# earlgrey register map
Vendor: lowRISC; File version: 0.1
CPU: ibex rev01, little endian, no MPU, no FPU, VTOR, 2 interrupt priority bits, 2 interrupts
Registers are 32-bit, read-write, no defined reset value unless marked. A register's access mark holds for its fields unless they carry their own. Offsets are from the block's base; [hi:lo] are bit positions.

## ENTROPY_SRC — Filters and checks raw entropy bits from a random noise source and forwards them to CSRNG
Base 0x41160000
0x40 ME_REGWEN — Register write enable for module enable register
  [0] Value — When true, the !!MODULE_ENABLE register can be modified.When false, it becomes read-only.
0x44 SW_REGUPD — Register write enable for control and threshold registers
  [0] Value — When this bit true and the MODULE_ENABLE field is false,the REGWEN write enable bit read as true, and is distributed toall associated control and threshold registers.When false, these registers become read-only.
0x48 REGWEN ro — Register write enable for all control registers
  [0] Value — This read-only write enable bit will allow write access to control and threshold registers that are associated with this bit, but only when the !!MODULE_ENABLE register is set to `kMultiBitBool4False` and the !!SW_REGUPD write enable bit is set to true.When read as false, these registers become read-only.
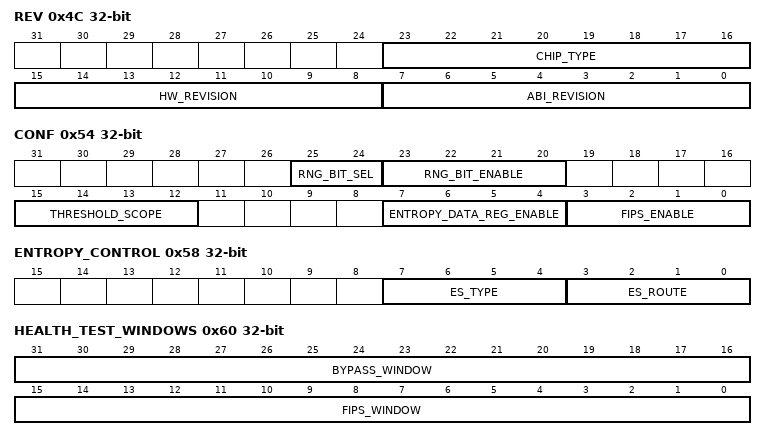
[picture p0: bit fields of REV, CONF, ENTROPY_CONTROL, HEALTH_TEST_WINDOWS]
0x4C REV ro — Revision register
  [23:16] CHIP_TYPE — Read of this register shows the type of chip using this block.
  [15:8] HW_REVISION — Read of this register shows the revision of this block.
  [7:0] ABI_REVISION — Read of this register shows the ABI of this block.
0x50 MODULE_ENABLE
  [3:0] MODULE_ENABLE — Setting this field to `kMultiBitBool4True` will enable the ENTROPY_SRC module. Setting this field to `kMultiBitBool4False` will effectively reset the module.The modules of the entropy complex may only be enabled and disabled in a specific order, see Programmers Guide for details.
0x54 CONF — Configuration register
  [25:24] RNG_BIT_SEL — When the above bit iset, this field selects which bit from the RNG bus willbe processed when in single RNG bit mode.This two bit field selects the RNG bit stream:0b00: RNG bit 00b01: RNG bit 10b10: RNG bit 20b11: RNG bit 3
  [23:20] RNG_BIT_ENABLE — Setting this field to `kMultiBitBool4True` enables the single RNG bit mode, where only one bit is sampled.Note that the ENTROPY_SRC block can only generate FIPS qualified entropy if this field is set to `kMultiBitBool4False`.Additional requirements to generate FIPS qualified entropy are i) that !!CONF.FIPS_ENABLE is set to `kMultiBitBool4True`, and ii) that at most one of the !!ENTROPY_CONTROL.ES_ROUTE and !!ENTROPY_CONTROL.ES_TYPE fields but not both are set to `kMultiBitBool4True`.
  [15:12] THRESHOLD_SCOPE — This field controls the scope (either by-line or by-sum) of the health checks.If set to `kMultiBitBool4True`, the Adaptive Proportion and Markov Tests will accumulate all RNG input lines into a single score, and thresholds will be applied to the sum all the entropy input lines.If set to `kMultiBitBool4False`, the RNG input lines are all scored individually.A statistical deviation in any one input line, be it due to coincidence or failure, will force rejection of the sample, and count toward the total alert count.
  [7:4] ENTROPY_DATA_REG_ENABLE — Setting this field to `kMultiBitBool4True` will enable reading entropy values from the !!ENTROPY_DATA register.This function also requires that the otp_en_entropy_src_fw_read input is set to `kMultiBitBool8True`.
  [3:0] FIPS_ENABLE — Setting this field to `kMultiBitBool4True` selects the FIPS/CC compliant mode (or short FIPS mode).In this mode, the ENTROPY_SRC block can generate FIPS qualified entropy.Additional requirements to generate FIPS qualified entropy are i) that at most one of the !!ENTROPY_CONTROL.ES_ROUTE and !!ENTROPY_CONTROL.ES_TYPE fields are set to `kMultiBitBool4True` but not both, and ii) that !!CONF.RNG_BIT_ENABLE is set to `kMultiBitBool4False`.Setting this field to `kMultiBitBool4False` selects the boot-time / bypass mode in which the hardware conditioning is bypassed.
0x58 ENTROPY_CONTROL
  [7:4] ES_TYPE — When this field is `kMultiBitBool4False`, the hardware conditioning inside the ENTROPY_SRC block is enabled.Setting this field to `kMultiBitBool4True` will bypass the hardware conditioning.For this to work, also !!ENTROPY_CONTROL.ES_ROUTE needs to be set to `kMultiBitBool4True` to route the unconditioned, raw entropy to the !!ENTROPY_DATA register.Alternatively, the hardware conditioning can be bypassed by setting !!CONF.FIPS_ENABLE to `kMultiBitBool4False` to disable FIPS mode and enable bypass / boot-time mode.In both cases, the ENTROPY_SRC block will not generate FIPS qualified entropy.To generate FIPS qualified entropy, i) !!CONF.FIPS_ENABLE needs to be set to `kMultiBitBool4True`, ii) !!CONF.RNG_BIT_ENABLE needs to be set to `kMultiBitBool4False`, and iii) at most one of the !!ENTROPY_CONTROL.ES_ROUTE and !!ENTROPY_CONTROL.ES_TYPE fields needs to be set to `kMultiBitBool4True` but not both.
  [3:0] ES_ROUTE — When this field is `kMultiBitBool4False`, the generated entropy will be forwarded out of this module to the hardware interface.Setting this field to `kMultiBitBool4True` routes the generated entropy to the !!ENTROPY_DATA register to be read by firmware.Note that for !!ENTROPY_DATA to become readable, also !!CONF.ENTROPY_DATA_REG_ENABLE needs to be set to `kMultiBitBool4True`.In addition, the otp_en_entropy_src_fw_read input needs to be set to `kMultiBitBool8True`.
0x5C ENTROPY_DATA ro — Entropy data bits
  [31:0] Value — A read of this register provides generated entropy bits to firmware.For this to work also !!CONF.ENTROPY_DATA_REG_ENABLE needs to be set to `kMultiBitBool4True`.In addition, the otp_en_entropy_src_fw_read input needs to be set to `kMultiBitBool8True`.
0x60 HEALTH_TEST_WINDOWS
  [31:16] BYPASS_WINDOW — This is the window size for all health tests when running in bypass mode.This mode is active after reset for the first and only test run, or when this mode is programmed by firmware by setting !!CONF.FIPS_ENABLE to `kMultiBitBool4False`.The default value is (384 bits * 1 clock/4 bits);Note that currently only a window size of 384 is supported and tested (this corresponds to the register default value 0x60).Do not use any other values, unless you know what you are doing.
  [15:0] FIPS_WINDOW — This is the window size for all health tests.This value is used when entropy is being tested in FIPS/CC compliance mode (for simplicity referred to as FIPS mode).The default value is (2048 bits * 1 clock/4 bits);
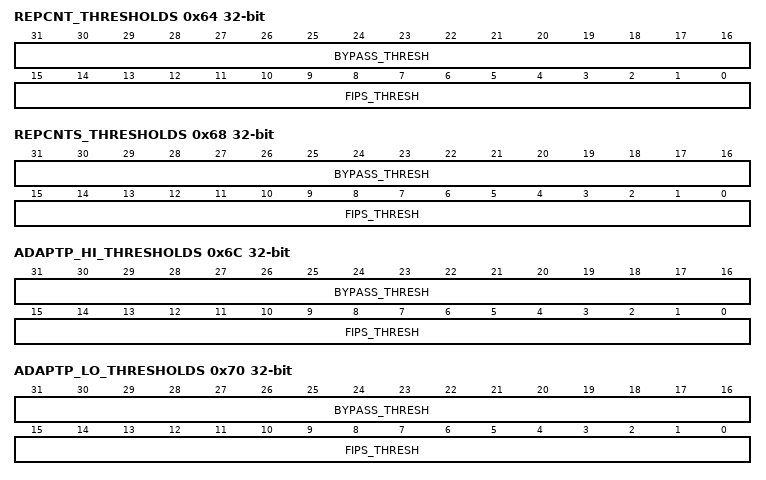
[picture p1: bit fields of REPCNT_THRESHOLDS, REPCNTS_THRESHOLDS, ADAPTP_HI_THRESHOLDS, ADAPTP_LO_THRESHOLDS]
0x64 REPCNT_THRESHOLDS — Repetition count test thresholds register
  [31:16] BYPASS_THRESH — This is the threshold size for the repetition count health test running in bypass mode. This mode is active after reset for the first and only test run, or when this mode is programmed by firmware. This register must be written before the module is enabled. Writing to this register will only update the register if the written value is less than the current value of this register. A read from this register always reflects the current value.
  [15:0] FIPS_THRESH — This is the threshold size for the repetition count health test. This value is used in FIPS mode. This register must be written before the module is enabled. Writing to this register will only update the register if the written value is less than the current value of this register. A read from this register always reflects the current value.
0x68 REPCNTS_THRESHOLDS — Repetition count symbol test thresholds register
  [31:16] BYPASS_THRESH — This is the threshold size for the repetition count symbol health test running in bypass mode. This mode is active after reset for the first and only test run, or when this mode is programmed by firmware. This register must be written before the module is enabled. Writing to this register will only update the register if the written value is less than the current value of this register. A read from this register always reflects the current value.
  [15:0] FIPS_THRESH — This is the threshold size for the repetition count symbol health test. This value is used in FIPS mode. This register must be written before the module is enabled. Writing to this register will only update the register if the written value is less than the current value of this register. A read from this register always reflects the current value.
0x6C ADAPTP_HI_THRESHOLDS — Adaptive proportion test high thresholds register
  [31:16] BYPASS_THRESH — This is the threshold size for the adaptive proportion health test running in bypass mode. This mode is active after reset for the first and only test run, or when this mode is programmed by firmware. This register must be written before the module is enabled. Writing to this register will only update the register if the written value is less than the current value of this register. A read from this register always reflects the current value.
  [15:0] FIPS_THRESH — This is the threshold size for the adaptive proportion health test. This value is used in FIPS mode. This register must be written before the module is enabled. Writing to this register will only update the register if the written value is less than the current value of this register. A read from this register always reflects the current value.
0x70 ADAPTP_LO_THRESHOLDS — Adaptive proportion test low thresholds register
  [31:16] BYPASS_THRESH — This is the threshold size for the adaptive proportion health test running in bypass mode. This mode is active after reset for the first and only test run, or when this mode is programmed by firmware. This register must be written before the module is enabled. Writing to this register will only update the register if the written value is greater than the current value of this register. A read from this register always reflects the current value.
  [15:0] FIPS_THRESH — This is the threshold size for the adaptive proportion health test. This value is used in FIPS mode. This register must be written before the module is enabled. Writing to this register will only update the register if the written value is greater than the current value of this register. A read from this register always reflects the current value.
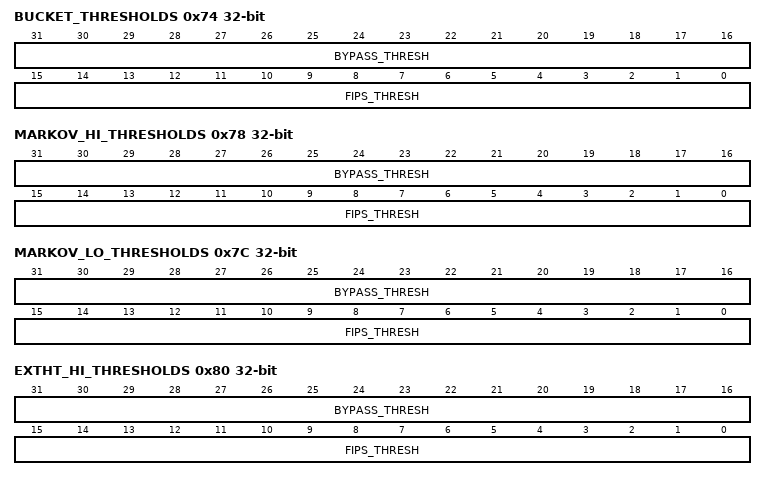
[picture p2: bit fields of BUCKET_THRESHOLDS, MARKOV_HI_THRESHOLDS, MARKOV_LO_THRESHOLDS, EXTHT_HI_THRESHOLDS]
0x74 BUCKET_THRESHOLDS — Bucket test thresholds register
  [31:16] BYPASS_THRESH — This is the threshold size for the bucket health test running in bypass mode. This mode is active after reset for the first and only test run, or when this mode is programmed by firmware. This register must be written before the module is enabled. Writing to this register will only update the register if the written value is less than the current value of this register. A read from this register always reflects the current value.
  [15:0] FIPS_THRESH — This is the threshold size for the bucket health test. This value is used in FIPS mode. This register must be written before the module is enabled. Writing to this register will only update the register if the written value is less than the current value of this register. A read from this register always reflects the current value.
0x78 MARKOV_HI_THRESHOLDS — Markov test high thresholds register
  [31:16] BYPASS_THRESH — This is the threshold size for the Markov health test running in bypass mode. This mode is active after reset for the first and only test run, or when this mode is programmed by firmware. This register must be written before the module is enabled. Writing to this register will only update the register if the written value is less than the current value of this register. A read from this register always reflects the current value.
  [15:0] FIPS_THRESH — This is the threshold size for the Markov health test. This value is used in FIPS mode. This register must be written before the module is enabled. Writing to this register will only update the register if the written value is less than the current value of this register. A read from this register always reflects the current value.
0x7C MARKOV_LO_THRESHOLDS — Markov test low thresholds register
  [31:16] BYPASS_THRESH — This is the threshold size for the Markov health test running in bypass mode. This mode is active after reset for the first and only test run, or when this mode is programmed by firmware. This register must be written before the module is enabled. Writing to this register will only update the register if the written value is greater than the current value of this register. A read from this register always reflects the current value.
  [15:0] FIPS_THRESH — This is the threshold size for the Markov health test. This value is used in FIPS mode. This register must be written before the module is enabled. Writing to this register will only update the register if the written value is greater than the current value of this register. A read from this register always reflects the current value.
0x80 EXTHT_HI_THRESHOLDS — External health test high thresholds register
  [31:16] BYPASS_THRESH — This is the threshold size for the external health test running in bypass mode. This mode is active after reset for the first and only test run, or when this mode is programmed by firmware. This register must be written before the module is enabled. Writing to this register will only update the register if the written value is less than the current value of this register. A read from this register always reflects the current value.
  [15:0] FIPS_THRESH — This is the threshold size for the external health test. This value is used in FIPS mode. This register must be written before the module is enabled. Writing to this register will only update the register if the written value is less than the current value of this register. A read from this register always reflects the current value.
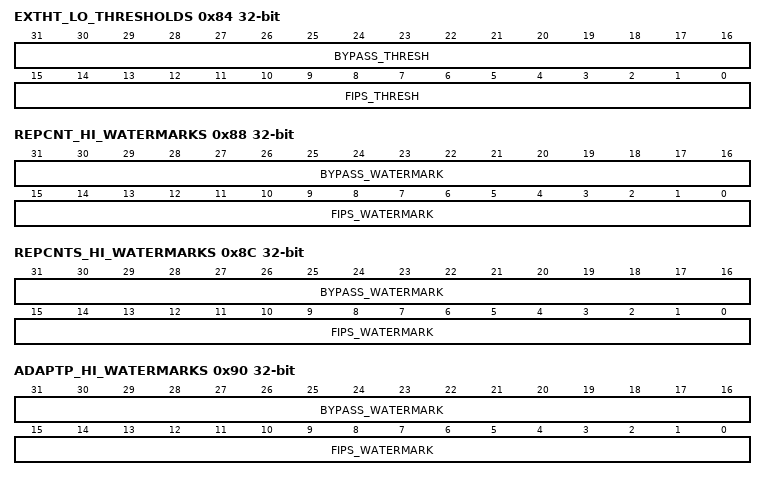
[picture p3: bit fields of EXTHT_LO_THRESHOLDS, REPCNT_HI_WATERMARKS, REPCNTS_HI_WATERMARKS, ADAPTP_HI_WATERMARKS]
0x84 EXTHT_LO_THRESHOLDS — External health test low thresholds register
  [31:16] BYPASS_THRESH — This is the threshold size for the external health test running in bypass mode. This mode is active after reset for the first and only test run, or when this mode is programmed by firmware. This register must be written before the module is enabled. Writing to this register will only update the register if the written value is greater than the current value of this register. A read from this register always reflects the current value.
  [15:0] FIPS_THRESH — This is the threshold size for the external health test. This value is used in FIPS mode. This register must be written before the module is enabled. Writing to this register will only update the register if the written value is greater than the current value of this register. A read from this register always reflects the current value.
0x88 REPCNT_HI_WATERMARKS ro — Repetition count test high watermarks register
  [31:16] BYPASS_WATERMARK — High watermark value of the REPCNT test in bypass mode.
  [15:0] FIPS_WATERMARK — High watermark value of the REPCNT test in FIPS mode.
0x8C REPCNTS_HI_WATERMARKS ro — Repetition count symbol test high watermarks register
  [31:16] BYPASS_WATERMARK — High watermark value of the REPCNTS test in bypass mode.
  [15:0] FIPS_WATERMARK — High watermark value of the REPCNTS test in FIPS mode.
0x90 ADAPTP_HI_WATERMARKS ro — Adaptive proportion test high watermarks register
  [31:16] BYPASS_WATERMARK — High watermark value of the adaptive proportion test in bypass mode.
  [15:0] FIPS_WATERMARK — High watermark value of the adaptive proportion test in FIPS mode.
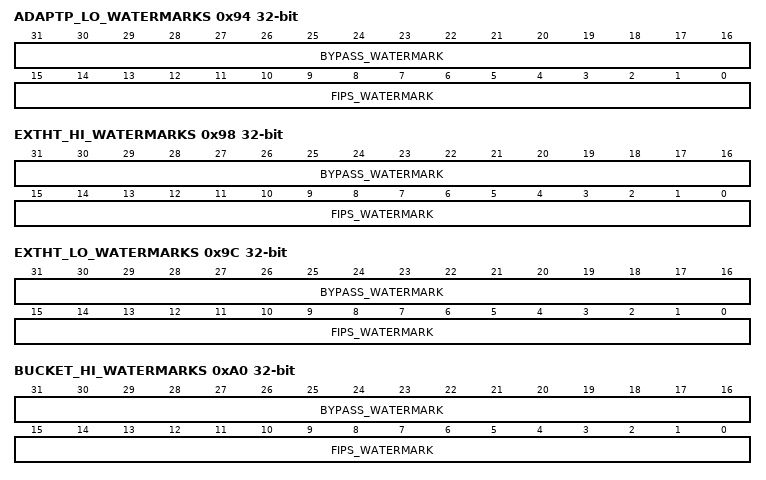
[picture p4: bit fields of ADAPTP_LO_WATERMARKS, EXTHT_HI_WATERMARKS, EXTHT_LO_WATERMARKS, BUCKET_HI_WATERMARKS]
0x94 ADAPTP_LO_WATERMARKS ro — Adaptive proportion test low watermarks register
  [31:16] BYPASS_WATERMARK — Low watermark value of the adaptive proportion test in bypass mode.
  [15:0] FIPS_WATERMARK — Low watermark value of the adaptive proportion test in FIPS mode.
0x98 EXTHT_HI_WATERMARKS ro — External health test high watermarks register
  [31:16] BYPASS_WATERMARK — High watermark value of the external health test in bypass mode.
  [15:0] FIPS_WATERMARK — High watermark value of the external health test in FIPS mode.
0x9C EXTHT_LO_WATERMARKS ro — External health test low watermarks register
  [31:16] BYPASS_WATERMARK — Low watermark value of the external health test in bypass mode.
  [15:0] FIPS_WATERMARK — Low watermark value of the external health test in FIPS mode.
0xA0 BUCKET_HI_WATERMARKS ro — Bucket test high watermarks register
  [31:16] BYPASS_WATERMARK — High watermark value of the bucket test in bypass mode.
  [15:0] FIPS_WATERMARK — High watermark value of the bucket test in FIPS mode.
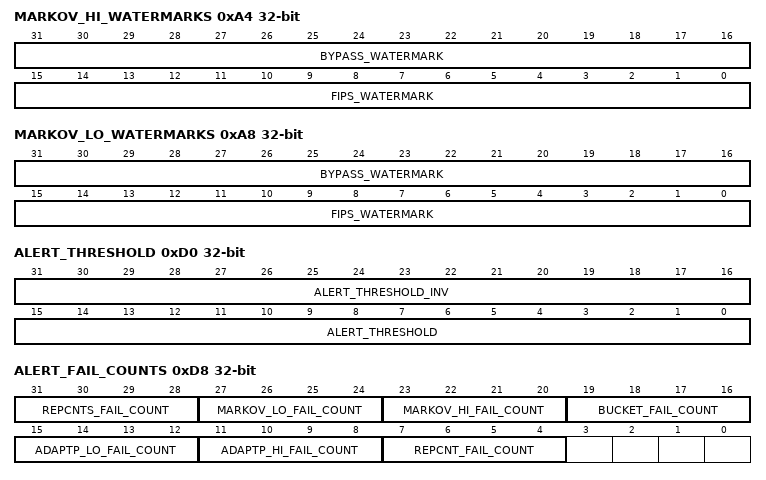
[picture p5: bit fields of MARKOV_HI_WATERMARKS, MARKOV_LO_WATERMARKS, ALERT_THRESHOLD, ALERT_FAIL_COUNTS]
0xA4 MARKOV_HI_WATERMARKS ro — Markov test high watermarks register
  [31:16] BYPASS_WATERMARK — High watermark value of the Markov test in bypass mode.
  [15:0] FIPS_WATERMARK — High watermark value of the Markov test in FIPS mode.
0xA8 MARKOV_LO_WATERMARKS ro — Markov test low watermarks register
  [31:16] BYPASS_WATERMARK — Low watermark value of the Markov test in bypass mode.
  [15:0] FIPS_WATERMARK — Low watermark value of the Markov test in FIPS mode.
0xAC REPCNT_TOTAL_FAILS ro — Repetition count test failure counter register
  [31:0] REPCNT_TOTAL_FAILS — This register will hold a running count of test failures observed during normal operation. It will persist until cleared.
0xB0 REPCNTS_TOTAL_FAILS ro — Repetition count symbol test failure counter register
  [31:0] REPCNTS_TOTAL_FAILS — This register will hold a running count of test failures observed during normal operation. It will persist until cleared.
0xB4 ADAPTP_HI_TOTAL_FAILS ro — Adaptive proportion high test failure counter register
  [31:0] ADAPTP_HI_TOTAL_FAILS — This register will hold a running count of test failures observed during normal operation. It will persist until cleared.
0xB8 ADAPTP_LO_TOTAL_FAILS ro — Adaptive proportion low test failure counter register
  [31:0] ADAPTP_LO_TOTAL_FAILS — This register will hold a running count of test failures observed during normal operation. It will persist until cleared.
0xBC BUCKET_TOTAL_FAILS ro — Bucket test failure counter register
  [31:0] BUCKET_TOTAL_FAILS — This register will hold a running count of test failures observed during normal operation. It will persist until cleared.
0xC0 MARKOV_HI_TOTAL_FAILS ro — Markov high test failure counter register
  [31:0] MARKOV_HI_TOTAL_FAILS — This register will hold a running count of test failures observed during normal operation. It will persist until cleared.
0xC4 MARKOV_LO_TOTAL_FAILS ro — Markov low test failure counter register
  [31:0] MARKOV_LO_TOTAL_FAILS — This register will hold a running count of test failures observed during normal operation. It will persist until cleared.
0xC8 EXTHT_HI_TOTAL_FAILS ro — External health test high threshold failure counter register
  [31:0] EXTHT_HI_TOTAL_FAILS — This register will hold a running count of test failures observed during normal operation. It will persist until cleared.
0xCC EXTHT_LO_TOTAL_FAILS ro — External health test low threshold failure counter register
  [31:0] EXTHT_LO_TOTAL_FAILS — This register will hold a running count of test failures observed during normal operation. It will persist until cleared.
0xD0 ALERT_THRESHOLD
  [31:16] ALERT_THRESHOLD_INV — This should be set to the value above, but inverted.
  [15:0] ALERT_THRESHOLD — This is the threshold size that will signal an alert when value is reached. A value of zero will disable alerts. The default value is 2.
0xD4 ALERT_SUMMARY_FAIL_COUNTS ro — Alert summary failure counts register
  [15:0] ANY_FAIL_COUNT — This field will hold a running count of the total alert count, which is a sum of all of the other counters in the !!ALERT_FAIL_COUNTS register. It will be reset after every passing test sequence unless in firmware override mode (extract and insert only). If an alert is signaled, this value will persist until it is cleared.
0xD8 ALERT_FAIL_COUNTS ro — Alert failure counts register
  [31:28] REPCNTS_FAIL_COUNT — This field will hold a running count of test failures that contribute to the total alert count. It will be reset after every passing test sequence unless in firmware override mode (extract and insert only). If an alert is signaled, this value will persist until it is cleared.
  [27:24] MARKOV_LO_FAIL_COUNT — This field will hold a running count of test failures that contribute to the total alert count. It will be reset after every passing test sequence unless in firmware override mode (extract and insert only). If an alert is signaled, this value will persist until it is cleared.
  [23:20] MARKOV_HI_FAIL_COUNT — This field will hold a running count of test failures that contribute to the total alert count. It will be reset after every passing test sequence unless in firmware override mode (extract and insert only). If an alert is signaled, this value will persist until it is cleared.
  [19:16] BUCKET_FAIL_COUNT — This field will hold a running count of test failures that contribute to the total alert count. It will be reset after every passing test sequence unless in firmware override mode (extract and insert only). If an alert is signaled, this value will persist until it is cleared.
  [15:12] ADAPTP_LO_FAIL_COUNT — This field will hold a running count of test failures that contribute to the total alert count. It will be reset after every passing test sequence unless in firmware override mode (extract and insert only). If an alert is signaled, this value will persist until it is cleared.
  [11:8] ADAPTP_HI_FAIL_COUNT — This field will hold a running count of test failures that contribute to the total alert count. It will be reset after every passing test sequence unless in firmware override mode (extract and insert only). If an alert is signaled, this value will persist until it is cleared.
  [7:4] REPCNT_FAIL_COUNT — This field will hold a running count of test failures that contribute to the total alert count. It will be reset after every passing test sequence unless in firmware override mode (extract and insert only). If an alert is signaled, this value will persist until it is cleared.
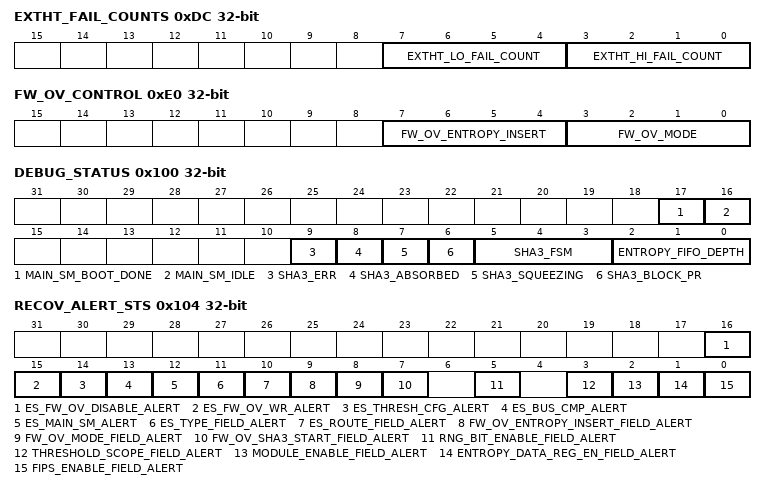
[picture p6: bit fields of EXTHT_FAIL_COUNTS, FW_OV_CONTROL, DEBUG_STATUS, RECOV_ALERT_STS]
0xDC EXTHT_FAIL_COUNTS ro — External health test alert failure counts register
  [7:4] EXTHT_LO_FAIL_COUNT — This field will hold a running count of test failures that contribute to the total alert count. It will be reset after every passing test sequence unless in firmware override mode (extract and insert only). If an alert is signaled, this value will persist until it is cleared.
  [3:0] EXTHT_HI_FAIL_COUNT — This field will hold a running count of test failures that contribute to the total alert count. It will be reset after every passing test sequence unless in firmware override mode (extract and insert only). If an alert is signaled, this value will persist until it is cleared.
0xE0 FW_OV_CONTROL — Firmware override control register
  [7:4] FW_OV_ENTROPY_INSERT — Setting this field to `kMultiBitBool4True` allows firmware to extract entropy bits by reading the observe FIFO (see !!FW_OV_RD_DATA) and insert entropy bits into the entropy flow by writing the !!FW_OV_WR_DATA register.This is useful e.g. for performing additional health tests and/or firmware-based conditioning.For this to work, !!FW_OV_CONTROL.FW_OV_MODE needs to be set to `kMultiBitBool4True`.In addition, the otp_en_entropy_src_fw_over input needs to be set to `kMultiBitBool8True`.Firmware can use the hardware conditioning for the inserted entropy bits (see !!FW_OV_SHA3_START).Note that if the field is set to `kMultiBitBool4True`, post-health test entropy bits do NOT continue to flow through the hardware pipeline.Also, the !!FW_OV_CONTROL.FW_OV_MODE bit must be set.The observe FIFO will collect 2 kBit of contiguous entropy bits.Any entropy bits arriving after the observe FIFO is full are being discarded.Firmware has to read out the entire observe FIFO to restart entropy collection.Only entropy bits inserted by firmware by writing !!FW_OV_WR_DATA may eventually reach the block hardware interface.
  [3:0] FW_OV_MODE — Setting this field to `kMultiBitBool4True` will put the entropy flow in firmware override mode.In this mode, firmware can monitor the post-health test entropy by readingthe observe FIFO (see !!FW_OV_RD_DATA).For this to work, the otp_en_entropy_src_fw_over input needs to be set to `kMultiBitBool8True`.Note that the post-health test entropy bits collected in the observe FIFO continue to flow through the hardware pipeline and may eventually reach the block hardware interface.
0xE4 FW_OV_SHA3_START — Firmware override sha3 block start control register
  [3:0] FW_OV_INSERT_START — Setting this field to `kMultiBitBool4True` will instruct the ENTROPY_SRC main state machine to start the SHA3 process and be ready to accept entropy data.This field should be set prior to writing the !!FW_OV_WR_DATA register.Once all data has been written, this field should be set to `kMultiBitBool4False`.Once that happened, the SHA3 block will finish processing and push the result into the esfinal FIFO.Note that clearing this bit to `kMultiBitBool4False` while there is still unprocessed entropy in !!FW_OV_WR_DATA will start the SHA3 engine before data can be added to the input message, and will also signal a recoverable alert in !!RECOV_ALERT_STS.ES_FW_OV_DISABLE_ALERT.To avoid this, check that !!FW_OV_WR_FIFO_FULL is clear before setting this field to `kMultiBitBool4False`.
0xE8 FW_OV_WR_FIFO_FULL ro — Firmware override FIFO write full status register
  [0] FW_OV_WR_FIFO_FULL — "When this bit is clear, writes to the FW_OV_WR_DATA register are allowed.If this bit is set, it is the equivalent to a FIFO full condition, and writesto the FW_OV_WR_DATA register must be delayed until this bit is reset.
0xEC FW_OV_RD_FIFO_OVERFLOW — Firmware override observe FIFO overflow status
  [0] FW_OV_RD_FIFO_OVERFLOW — This bit is set by hardware whenever RNG data is lost due to an overflow conditionin the observe FIFO. The RNG data rate is slow enough that firmware should alwaysbe able to keep up. This register meanwhile provides an additional check to confirmthat bytes read from the !!FW_OV_RD_DATA register represent contiguous RNG samples.If an overflow event occurs, this bit must be cleared by software.
0xF0 FW_OV_RD_DATA ro — Firmware override observe FIFO read register
  [31:0] Value — A read of this register pops and returns the top of the observe FIFO.For this to work, the !!FW_OV_CONTROL.FW_OV_MODE field needs to be set to `kMultiBitBool4True`In addition, the otp_en_entropy_src_fw_over input needs to be set to `kMultiBitBool8True`.
0xF4 FW_OV_WR_DATA wo — Firmware override FIFO write register
  [31:0] Value — A write to this register will insert entropy back into the entropy source module flow.For this to work, both the !!FW_OV_CONTROL.FW_OV_MODE and !!FW_OV_CONTROL.FW_OV_ENTROPY_INSERT fields need to be set to `kMultiBitBool4True`.In addition, the otp_en_entropy_src_fw_over input needs to be set to `kMultiBitBool8True`.
0xF8 OBSERVE_FIFO_THRESH — Observe FIFO threshold register
  [6:0] Value — This field will set the threshold that the depth of the observe FIFOwill be compared with when setting the interrupt status bit.Note: a value of zero is reserved and not to be used.
0xFC OBSERVE_FIFO_DEPTH ro
  [6:0] Value — This field will hold the current depth of the observe FIFO.
0x100 DEBUG_STATUS ro
  [17] MAIN_SM_BOOT_DONE — The entropy_src main state machine is in the boot phase done state.
  [16] MAIN_SM_IDLE — The entropy_src main state machine is in the idle state.
  [9] SHA3_ERR — This is a logic-or of all of the SHA3 error signals.
  [8] SHA3_ABSORBED — This is the SHA3 absorbed signal current state.
  [7] SHA3_SQUEEZING — This is the SHA3 squeezing signal current state.
  [6] SHA3_BLOCK_PR — This is the SHA3 block processed signal current state.
  [5:3] SHA3_FSM — This is the SHA3 finite state machine current state.
  [2:0] ENTROPY_FIFO_DEPTH — This is the depth of the entropy source FIFO.
0x104 RECOV_ALERT_STS — Recoverable alert status register
  [16] ES_FW_OV_DISABLE_ALERT — This bit is set when !!FW_OV_SHA3_START has been set to `kMultiBitBool4False`, without waiting for the bypass packer FIFO to clear.The final entropy entry in the FIFO will not be included in the SHA3 digest.(Rather it will be added to the subsequent SHA3 digest.)To avoid this alert, monitor !!FW_OV_WR_FIFO_FULL before clearing !!FW_OV_SHA3_START.This alert only applies when both !!FW_OV_CONTROL.FW_OV_MODE and !!FW_OV_CONTROL.FW_OV_ENTROPY_INSERT are set to `kMultiBitBool4True`.Writing a zero resets this status bit.
  [15] ES_FW_OV_WR_ALERT — This bit is set when the packer FIFO has been written but was full at the time,and in both FW_OV_MODE and FW_OV_ENTROPY_INSERT modes.This alert would normally be the result of not monitoring the !!FW_OV_WR_FIFO_FULLregister before each write to the !!FW_OV_WR_DATA register.Writing a zero resets this status bit.
  [14] ES_THRESH_CFG_ALERT — This bit is set when the !!ALERT_THRESHOLD register is not configured properly.The upper field must be the exact inverse of the lower field.Writing a zero resets this status bit.
  [13] ES_BUS_CMP_ALERT — This bit is set when the interal entropy bus value is equal to the priorvalid value on the bus, indicating a possible attack.Writing a zero resets this status bit.
  [12] ES_MAIN_SM_ALERT — This bit is set when the main state machine detects a threshhold failure state.Writing a zero resets this status bit.
  [11] ES_TYPE_FIELD_ALERT — This bit is set when the ES_TYPE field in the !!ENTROPY_CONTROL register is set to a value other than `kMultiBitBool4False` or `kMultiBitBool4True`.Writing a zero resets this status bit.
  [10] ES_ROUTE_FIELD_ALERT — This bit is set when the ES_ROUTE field in the !!ENTROPY_CONTROL register is set to a value other than `kMultiBitBool4False` or `kMultiBitBool4True`.Writing a zero resets this status bit.
  [9] FW_OV_ENTROPY_INSERT_FIELD_ALERT — This bit is set when the FW_OV_ENTROPY_INSERT field in the !!FW_OV_CONTROL register is set to a value other than `kMultiBitBool4False` or `kMultiBitBool4True`.Writing a zero resets this status bit.
  [8] FW_OV_MODE_FIELD_ALERT — This bit is set when the FW_OV_MODE field in the !!FW_OV_CONTROL register is set to a value other than `kMultiBitBool4False` or `kMultiBitBool4True`.Writing a zero resets this status bit.
  [7] FW_OV_SHA3_START_FIELD_ALERT — This bit is set when the FW_OV_SHA3_START field in the !!FW_OV_SHA3_START register is set to a value other than `kMultiBitBool4False` or `kMultiBitBool4True`.Writing a zero resets this status bit.
  [5] RNG_BIT_ENABLE_FIELD_ALERT — This bit is set when the RNG_BIT_ENABLE field in the !!CONF register is set to a value other than `kMultiBitBool4False` or `kMultiBitBool4True`.Writing a zero resets this status bit.
  [3] THRESHOLD_SCOPE_FIELD_ALERT — This bit is set when the THRESHOLD_SCOPE field in the !!CONF register is set to a value other than `kMultiBitBool4False` or `kMultiBitBool4True`.Writing a zero resets this status bit.
  [2] MODULE_ENABLE_FIELD_ALERT — This bit is set when the MODULE_ENABLE field in the !!MODULE_ENABLE register is set to a value other than `kMultiBitBool4False` or `kMultiBitBool4True`.Writing a zero resets this status bit.
  [1] ENTROPY_DATA_REG_EN_FIELD_ALERT — This bit is set when the ENTROPY_DATA_REG_ENABLE field in the !!CONF register is set to a value other than `kMultiBitBool4False` or `kMultiBitBool4True`.Writing a zero resets this status bit.
  [0] FIPS_ENABLE_FIELD_ALERT — This bit is set when the FIPS_ENABLE field in the !!CONF register is set to a value other than `kMultiBitBool4False` or `kMultiBitBool4True`.Writing a zero resets this status bit.
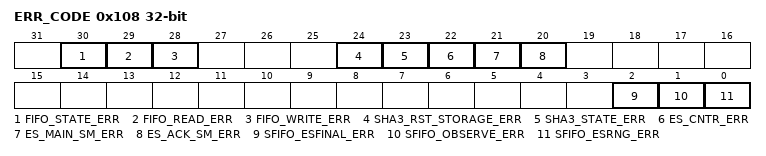
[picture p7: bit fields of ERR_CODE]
0x108 ERR_CODE ro — Hardware detection of error conditions status register
  [30] FIFO_STATE_ERR — This bit will be set to one when any of the source bits (bits 0 through 1 of thisthis register) are asserted as a result of an error pulse generated fromany FIFO where both the empty and full status bits are set.This bit will stay set until the next reset.
  [29] FIFO_READ_ERR — This bit will be set to one when any of the source bits (bits 0 through 1 of thisthis register) are asserted as a result of an error pulse generated fromany empty FIFO that has recieved a read pulse.This bit will stay set until the next reset.
  [28] FIFO_WRITE_ERR — This bit will be set to one when any of the source bits (bits 0 through 1 of thisthis register) are asserted as a result of an error pulse generated fromany full FIFO that has been recieved a write pulse.This bit will stay set until the next reset.
  [24] SHA3_RST_STORAGE_ERR — This bit will be set to one when a SHA3_RST_STORAGE_ERR signal beingactive has been detected.This error will signal a fatal alert, and also an interrupt if enabled.This bit will stay set until the next reset.
  [23] SHA3_STATE_ERR — This bit will be set to one when a SHA3 state error has been detected.This error will signal a fatal alert, and also an interrupt if enabled.This bit will stay set until the next reset.
  [22] ES_CNTR_ERR — This bit will be set to one when a hardened counter has detected an errorcondition. This error will signal a fatal alert, and alsoan interrupt if enabled.This bit will stay set until the next reset.
  [21] ES_MAIN_SM_ERR — This bit will be set to one when an illegal state has been detected for theES main stage state machine. This error will signal a fatal alert, and alsoan interrupt if enabled.This bit will stay set until the next reset.
  [20] ES_ACK_SM_ERR — This bit will be set to one when an illegal state has been detected for theES ack stage state machine. This error will signal a fatal alert, and alsoan interrupt if enabled.This bit will stay set until the next reset.
  [2] SFIFO_ESFINAL_ERR — This bit will be set to one when an error has been detected for theesfinal FIFO. The type of error is reflected in the type statusbits (bits 28 through 30 of this register).This bit will stay set until the next reset.
  [1] SFIFO_OBSERVE_ERR — This bit will be set to one when an error has been detected for theobserve FIFO. The type of error is reflected in the type statusbits (bits 28 through 30 of this register).This bit will stay set until the next reset.
  [0] SFIFO_ESRNG_ERR — This bit will be set to one when an error has been detected for theesrng FIFO. The type of error is reflected in the type statusbits (bits 28 through 30 of this register).This bit will stay set until the next reset.
0x10C ERR_CODE_TEST — Test error conditions register
  [4:0] ERR_CODE_TEST — Setting this field will set the bit number for which an errorwill be forced in the hardware. This bit number is that same onefound in the !!ERR_CODE register. The action of writing thisregister will force an error pulse. The sole purpose of thisregister is to test that any error properly propagates to eitheran interrupt or an alert.
0x110 MAIN_SM_STATE ro — Main state machine state debug register
  [8:0] MAIN_SM_STATE — This is the state of the ENTROPY_SRC main state machine.See the RTL file `entropy_src_main_sm` for the meaning of the values.
